# PIC16LF819 register map
Vendor: Microchip
Architecture 16xxxx. Special function registers and configuration words.
Registers are 8-bit, read-write, no defined reset value unless marked. A register's access mark holds for its fields unless they carry their own. Addresses are absolute, and some are shared; only a register's first bit layout is shown; lines under a group give offsets from that group; [hi:lo] are bit positions; {n}, {i} and the like mark numbered series; 'fields as' and 'values as' point back to an identical list; <NAME> marks a mode.

## Further device data
pins=1: RA2/AN2/Vref-; 2: RA3/AN3/Vref+; 3: RA4/AN4/T0CKI; 4: RA5/MCLR/Vpp; 5: Vss; 6: RB0/INT; 7: RB1/SDI/SDA; 8: RB2/SDO/CCP1; 9: RB3/CCP1/PGM; 10: RB4/SCK/SCL; 11: RB5/SS; 12: RB6/T1OSO/T1CKI/PGC; 13: RB7/T1OSI/PGD; 14: Vdd; 15: RA6/OSC2/CLKO; 16: RA7/OSC1/CLKI; 17: RA0/AN0; 18: RA1/AN1

## SFR
0x00 INDF access not given
0x01 TMR0 — (power-on value xxxxxxxx)
0x02 PCL reset 0x0
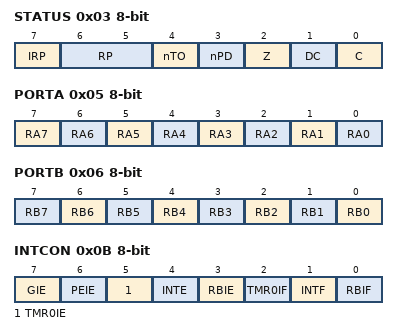
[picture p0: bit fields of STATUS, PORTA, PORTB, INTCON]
0x03 STATUS — (power-on value 00011xxx)
  [7] IRP, [6:5] RP, [4] nTO ro, [3] nPD ro, [2] Z, [1] DC, [0] C
0x04 FSR — (power-on value xxxxxxxx)
0x05 PORTA — (power-on value xxx00000)
  [7] RA7, [6] RA6, [5] RA5 ro, [n] RA{n} (n=0..4)
0x06 PORTB — (power-on value xxxxxxxx)
  [n] RB{n} (n=0..7)
0x0A PCLATH reset 0x0
  [4:0] PCLATH
0x0B INTCON — (power-on value 0000000x)
  [7] GIE, [6] PEIE, [5] TMR0IE, [4] INTE, [3] RBIE, [2] TMR0IF, [1] INTF, [0] RBIF
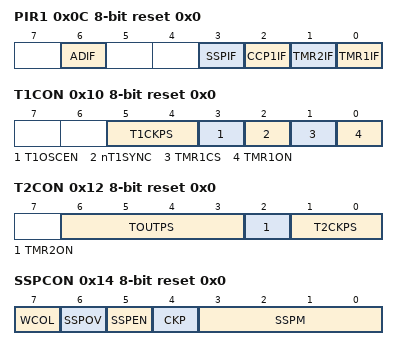
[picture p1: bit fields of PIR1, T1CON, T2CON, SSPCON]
0x0C PIR1 reset 0x0
  [6] ADIF, [3] SSPIF, [2] CCP1IF, [1] TMR2IF, [0] TMR1IF
0x0D PIR2 reset 0x0
  [4] EEIF
0x0E TMR1L — (power-on value xxxxxxxx)
0x0F TMR1H — (power-on value xxxxxxxx)
0x10 T1CON reset 0x0
  [5:4] T1CKPS, [3] T1OSCEN, [2] nT1SYNC, [1] TMR1CS, [0] TMR1ON
0x11 TMR2 reset 0x0
0x12 T2CON reset 0x0
  [6:3] TOUTPS, [2] TMR2ON, [1:0] T2CKPS
0x13 SSPBUF — (power-on value xxxxxxxx)
0x14 SSPCON reset 0x0
  [7] WCOL, [6] SSPOV, [5] SSPEN, [4] CKP, [3:0] SSPM
0x15 CCPR1L — (power-on value xxxxxxxx)
0x16 CCPR1H — (power-on value xxxxxxxx)
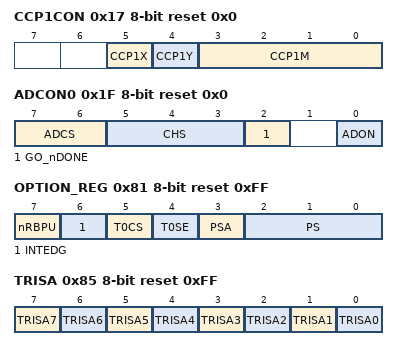
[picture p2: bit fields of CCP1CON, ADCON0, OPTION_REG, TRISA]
0x17 CCP1CON reset 0x0
  [5] CCP1X, [4] CCP1Y, [3:0] CCP1M
0x1E ADRESH — (power-on value xxxxxxxx)
0x1F ADCON0 reset 0x0
  [7:6] ADCS, [5:3] CHS, [2] GO_nDONE, [0] ADON
0x81 OPTION_REG reset 0xFF
  [7] nRBPU, [6] INTEDG, [5] T0CS, [4] T0SE, [3] PSA, [2:0] PS
0x85 TRISA reset 0xFF
  [7] TRISA7, [6] TRISA6, [5] TRISA5 ro, [n] TRISA{n} (n=0..4)
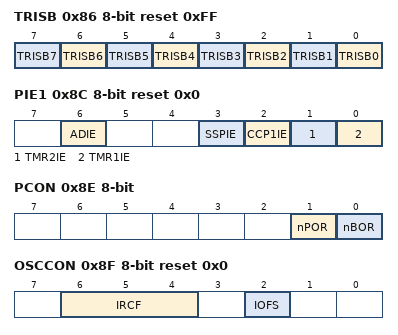
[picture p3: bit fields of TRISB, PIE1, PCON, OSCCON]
0x86 TRISB reset 0xFF
  [n] TRISB{n} (n=0..7)
0x8C PIE1 reset 0x0
  [6] ADIE, [3] SSPIE, [2] CCP1IE, [1] TMR2IE, [0] TMR1IE
0x8D PIE2 reset 0x0
  [4] EEIE
0x8E PCON — (power-on value ------qq)
  [1] nPOR, [0] nBOR
0x8F OSCCON reset 0x0
  [6:4] IRCF, [2] IOFS
0x90 OSCTUNE reset 0x0
  [5:0] TUN
0x92 PR2 reset 0xFF
0x93 SSPADD reset 0x0
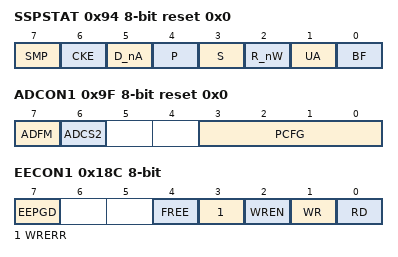
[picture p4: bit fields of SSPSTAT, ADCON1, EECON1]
0x94 SSPSTAT reset 0x0
  [7] SMP, [6] CKE, [5] D_nA, [4] P, [3] S, [2] R_nW, [1] UA, [0] BF
0x9E ADRESL — (power-on value xxxxxxxx)
0x9F ADCON1 reset 0x0
  [7] ADFM, [6] ADCS2, [3:0] PCFG
0x10C EEDATA — (power-on value xxxxxxxx)
0x10D EEADR — (power-on value xxxxxxxx)
0x10E EEDATH — (power-on value --xxxxxx)
  [5:0] EEDATH
0x10F EEADRH — (power-on value -----xxx)
  [2:0] EEADRH
0x18C EECON1 — (power-on value x--xx000)
  [7] EEPGD
  [4] FREE
  [3] WRERR
  [2] WREN
  [1] WR — (can only be set)
  [0] RD — (can only be set)
0x18D EECON2 wo

## CONFIG — Configuration words, addresses in ProgramSpace
0x2007 CONFIG 14-bit reset 0x3FFF
  [13] CP — Flash Program Memory Code Protection bit
    1=OFF (Code protection off); 0=ON (All memory locations code-protected)
  [12] CCPMX — CCP1 Pin Selection bit
    1=RB2 (CCP1 function on RB2); 0=RB3 (CCP1 function on RB3)
  [11] DEBUG — In-Circuit Debugger Mode bit
    1=OFF (In-Circuit Debugger disabled, RB6 and RB7 are general purpose I/O pins); 0=ON (In-Circuit Debugger enabled, RB6 and RB7 are dedicated to the debugger)
  [10:9] WRT — Flash Program Memory Write Enable bits
    3=OFF (Write protection off); 2=0000h to 01FFh write-protected, 0200h to 07FFh may be modified by EECON control; 1=0000h to 03FFh write-protected, 0400h to 07FFh may be modified by EECON control; 0=0000h to 05FFh write-protected, 0600h to 07FFh may be modified by EECON control
  [8] CPD — Data EE Memory Code Protection bit
    1=OFF (Code protection off); 0=ON (Data EE memory locations code-protected)
  [7] LVP — Low-Voltage Programming Enable bit
    1=ON (RB3/PGM pin has PGM function, Low-Voltage Programming enabled); 0=OFF (RB3/PGM pin has digital I/O function, HV on MCLR must be used for programming)
  [6] BOREN — Brown-out Reset Enable bit
    1=ON (BOR enabled); 0=OFF (BOR disabled)
  [5] MCLRE — RA5/MCLR/VPP Pin Function Select bit
    1=ON (RA5/MCLR/VPP pin function is MCLR); 0=OFF (RA5/MCLR/VPP pin function is digital I/O, MCLR internally tied to VDD)
  [3] PWRTE — Power-up Timer Enable bit
    1=OFF (PWRT disabled); 0=ON (PWRT enabled)
  [2] WDTE — Watchdog Timer Enable bit
    1=ON (WDT enabled); 0=OFF (WDT disabled)
  [4:0] FOSC — Oscillator Selection bits
    0b1xx11=EXTRCCLK (EXTRC oscillator; CLKO function on RA6/OSC2/CLKO pin); 0b1xx10=EXTRCIO (EXTRC oscillator; port I/O function on RA6/OSC2/CLKO pin); 0b1xx01=INTOSCCLK (INTRC oscillator; CLKO function on RA6/OSC2/CLKO pin and port I/O function on RA7/OSC1/CLKI pin); 0b1xx00=INTOSCIO (INTRC oscillator; port I/O function on both RA6/OSC2/CLKO pin and RA7/OSC1/CLKI pin); 0b0xx11=EC (EXTCLK; port I/O function on RA6/OSC2/CLKO pin); 0b0xx10=HS (HS oscillator); 0b0xx01=XT (XT oscillator); 0b0xx00=LP (LP oscillator)
